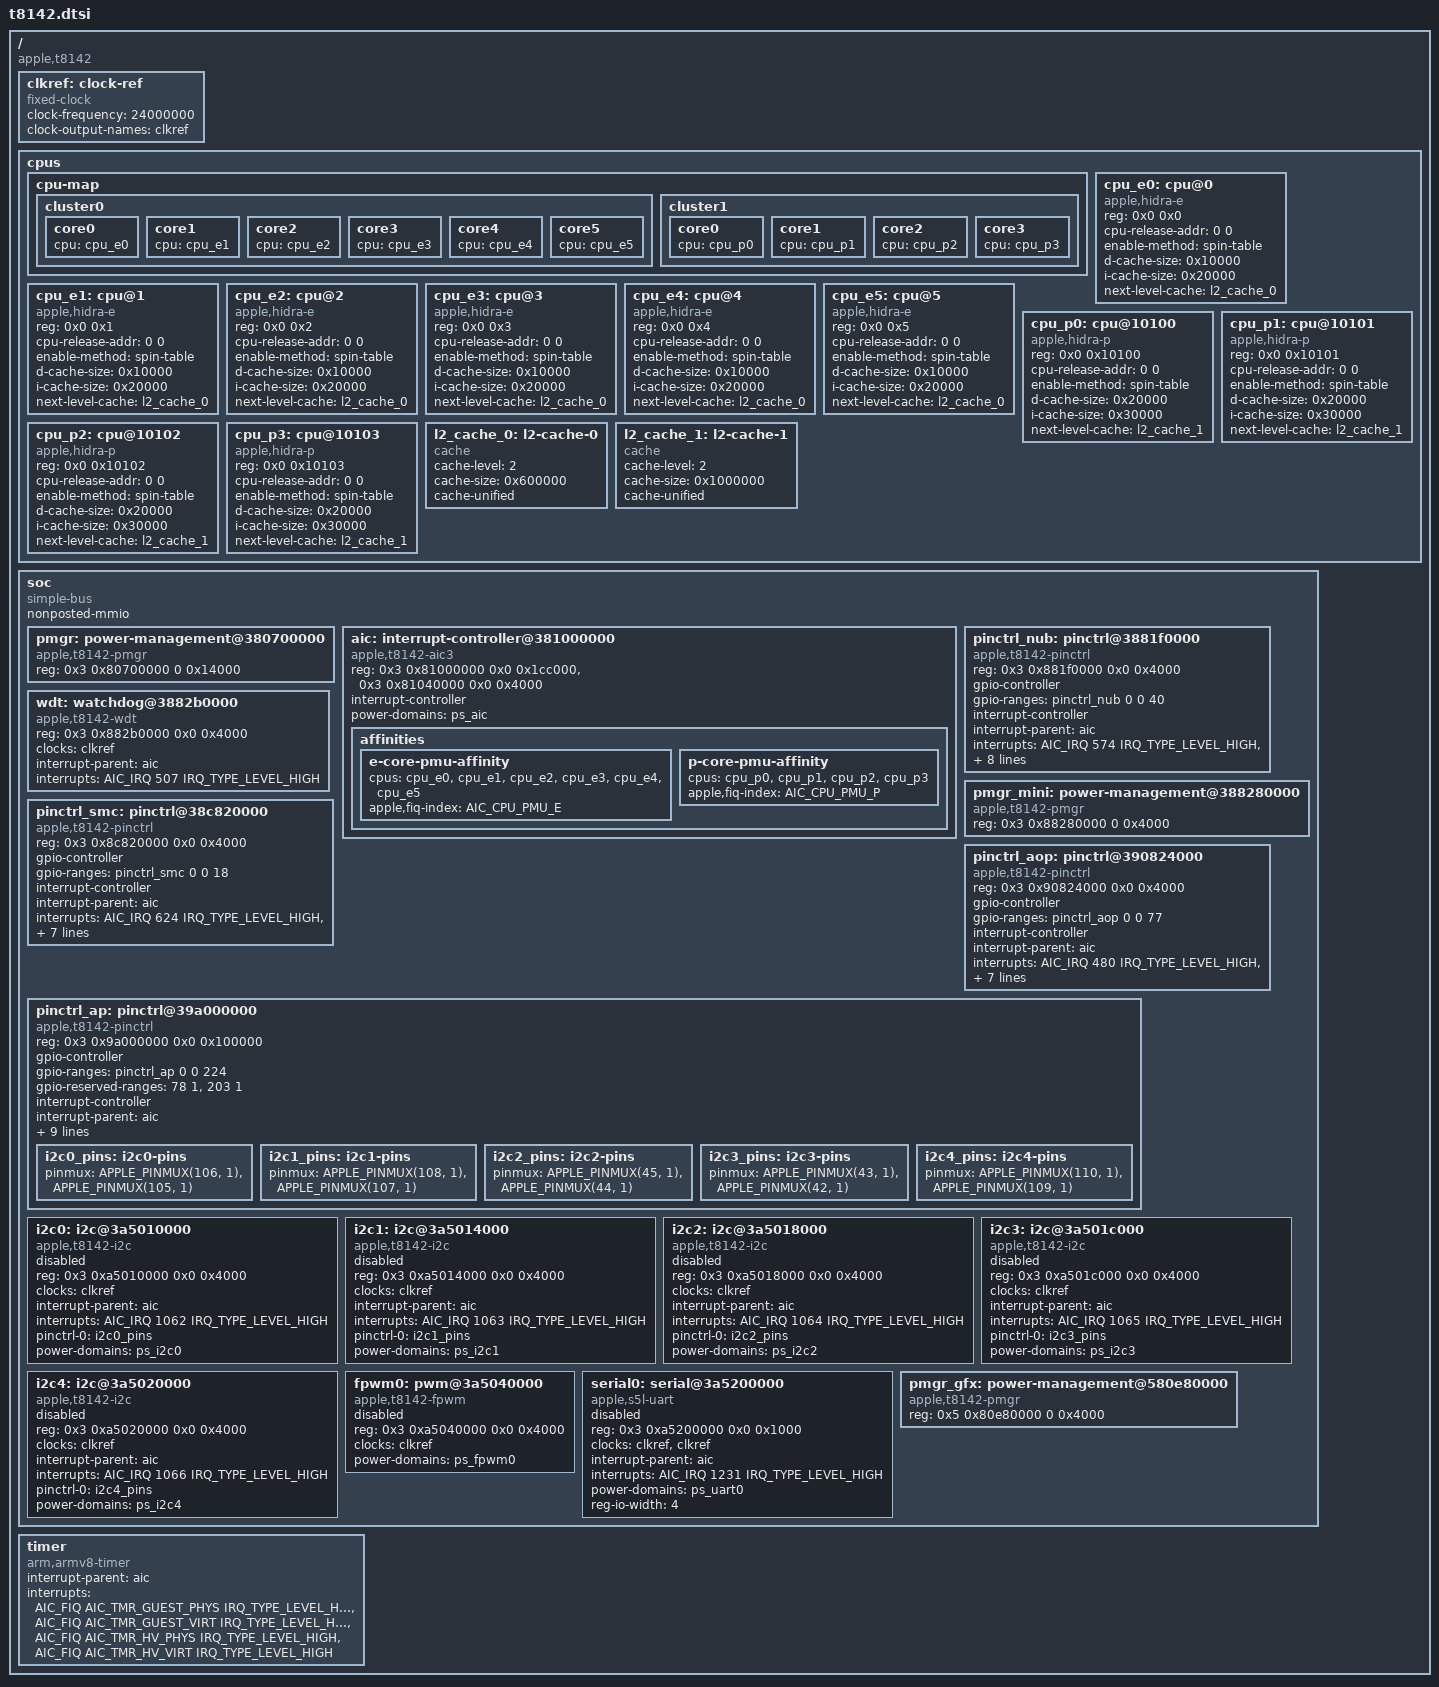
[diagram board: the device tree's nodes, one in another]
// SPDX-License-Identifier: GPL-2.0+ OR MIT
/*
 * Apple T8142 "M5" SoC
 *
 * Copyright The Asahi Linux Contributors
 */

#include <dt-bindings/interrupt-controller/apple-aic.h>
#include <dt-bindings/interrupt-controller/irq.h>
#include <dt-bindings/pinctrl/apple.h>

/ {
	compatible = "apple,t8142", "apple,arm-platform";

	#address-cells = <2>;
	#size-cells = <2>;

	clkref: clock-ref {
		compatible = "fixed-clock";
		#clock-cells = <0>;
		clock-frequency = <24000000>;
		clock-output-names = "clkref";
	};

	cpus {
		#address-cells = <2>;
		#size-cells = <0>;

		cpu-map {
			cluster0 {
				core0 {
					cpu = <&cpu_e0>;
				};

				core1 {
					cpu = <&cpu_e1>;
				};

				core2 {
					cpu = <&cpu_e2>;
				};

				core3 {
					cpu = <&cpu_e3>;
				};

				core4 {
					cpu = <&cpu_e4>;
				};

				core5 {
					cpu = <&cpu_e5>;
				};
			};

			cluster1 {
				core0 {
					cpu = <&cpu_p0>;
				};

				core1 {
					cpu = <&cpu_p1>;
				};

				core2 {
					cpu = <&cpu_p2>;
				};

				core3 {
					cpu = <&cpu_p3>;
				};
			};
		};

		cpu_e0: cpu@0 {
			device_type = "cpu";
			compatible = "apple,hidra-e";
			reg = <0x0 0x0>;
			cpu-release-addr = <0 0>;
			enable-method = "spin-table";

			d-cache-size = <0x10000>;
			i-cache-size = <0x20000>;
			next-level-cache = <&l2_cache_0>;
		};

		cpu_e1: cpu@1 {
			device_type = "cpu";
			compatible = "apple,hidra-e";
			reg = <0x0 0x1>;
			cpu-release-addr = <0 0>;
			enable-method = "spin-table";

			d-cache-size = <0x10000>;
			i-cache-size = <0x20000>;
			next-level-cache = <&l2_cache_0>;
		};

		cpu_e2: cpu@2 {
			device_type = "cpu";
			compatible = "apple,hidra-e";
			reg = <0x0 0x2>;
			cpu-release-addr = <0 0>;
			enable-method = "spin-table";

			d-cache-size = <0x10000>;
			i-cache-size = <0x20000>;
			next-level-cache = <&l2_cache_0>;
		};

		cpu_e3: cpu@3 {
			device_type = "cpu";
			compatible = "apple,hidra-e";
			reg = <0x0 0x3>;
			cpu-release-addr = <0 0>;
			enable-method = "spin-table";

			d-cache-size = <0x10000>;
			i-cache-size = <0x20000>;
			next-level-cache = <&l2_cache_0>;
		};

		cpu_e4: cpu@4 {
			device_type = "cpu";
			compatible = "apple,hidra-e";
			reg = <0x0 0x4>;
			cpu-release-addr = <0 0>;
			enable-method = "spin-table";

			d-cache-size = <0x10000>;
			i-cache-size = <0x20000>;
			next-level-cache = <&l2_cache_0>;
		};

		cpu_e5: cpu@5 {
			device_type = "cpu";
			compatible = "apple,hidra-e";
			reg = <0x0 0x5>;
			cpu-release-addr = <0 0>;
			enable-method = "spin-table";

			d-cache-size = <0x10000>;
			i-cache-size = <0x20000>;
			next-level-cache = <&l2_cache_0>;
		};

		cpu_p0: cpu@10100 {
			device_type = "cpu";
			compatible = "apple,hidra-p";
			reg = <0x0 0x10100>;
			cpu-release-addr = <0 0>;
			enable-method = "spin-table";

			d-cache-size = <0x20000>;
			i-cache-size = <0x30000>;
			next-level-cache = <&l2_cache_1>;
		};

		cpu_p1: cpu@10101 {
			device_type = "cpu";
			compatible = "apple,hidra-p";
			reg = <0x0 0x10101>;
			cpu-release-addr = <0 0>;
			enable-method = "spin-table";

			d-cache-size = <0x20000>;
			i-cache-size = <0x30000>;
			next-level-cache = <&l2_cache_1>;
		};

		cpu_p2: cpu@10102 {
			device_type = "cpu";
			compatible = "apple,hidra-p";
			reg = <0x0 0x10102>;
			cpu-release-addr = <0 0>;
			enable-method = "spin-table";

			d-cache-size = <0x20000>;
			i-cache-size = <0x30000>;
			next-level-cache = <&l2_cache_1>;
		};

		cpu_p3: cpu@10103 {
			device_type = "cpu";
			compatible = "apple,hidra-p";
			reg = <0x0 0x10103>;
			cpu-release-addr = <0 0>;
			enable-method = "spin-table";

			d-cache-size = <0x20000>;
			i-cache-size = <0x30000>;
			next-level-cache = <&l2_cache_1>;
		};

		l2_cache_0: l2-cache-0 {
			compatible = "cache";
			cache-level = <2>;
			cache-size = <0x600000>;
			cache-unified;
		};

		l2_cache_1: l2-cache-1 {
			compatible = "cache";
			cache-level = <2>;
			cache-size = <0x1000000>;
			cache-unified;
		};
	};

	soc: soc {
		compatible = "simple-bus";
		ranges;
		#address-cells = <2>;
		nonposted-mmio;
		#size-cells = <2>;

		pmgr: power-management@380700000 {
			compatible = "apple,t8142-pmgr", "apple,t8103-pmgr",
			             "syscon", "simple-mfd";
			reg = <0x3 0x80700000 0 0x14000>;
			#address-cells = <1>;
			#size-cells = <1>;
			/* child nodes are added in t8142-pmgr.dtsi */
		};

		aic: interrupt-controller@381000000 {
			compatible = "apple,t8142-aic3", "apple,t8122-aic3";
			reg = <0x3 0x81000000 0x0 0x1cc000>,
			      <0x3 0x81040000 0x0 0x4000>;
			reg-names = "core", "event";
			#interrupt-cells = <3>;
			interrupt-controller;
			power-domains = <&ps_aic>;

			affinities {
				e-core-pmu-affinity {
					cpus = <&cpu_e0 &cpu_e1 &cpu_e2
					        &cpu_e3 &cpu_e4 &cpu_e5>;
					apple,fiq-index = <AIC_CPU_PMU_E>;
				};

				p-core-pmu-affinity {
					cpus = <&cpu_p0 &cpu_p1
					        &cpu_p2 &cpu_p3>;
					apple,fiq-index = <AIC_CPU_PMU_P>;
				};
			};
		};

		pinctrl_nub: pinctrl@3881f0000 {
			compatible = "apple,t8142-pinctrl",
			             "apple,t8140-pinctrl";
			reg = <0x3 0x881f0000 0x0 0x4000>;

			#gpio-cells = <2>;
			gpio-controller;
			gpio-ranges = <&pinctrl_nub 0 0 40>;

			#interrupt-cells = <2>;
			interrupt-controller;
			interrupt-parent = <&aic>;
			interrupts = <AIC_IRQ 574 IRQ_TYPE_LEVEL_HIGH>,
			             <AIC_IRQ 575 IRQ_TYPE_LEVEL_HIGH>,
			             <AIC_IRQ 576 IRQ_TYPE_LEVEL_HIGH>,
			             <AIC_IRQ 577 IRQ_TYPE_LEVEL_HIGH>,
			             <AIC_IRQ 578 IRQ_TYPE_LEVEL_HIGH>,
			             <AIC_IRQ 579 IRQ_TYPE_LEVEL_HIGH>,
			             <AIC_IRQ 580 IRQ_TYPE_LEVEL_HIGH>;

			power-domains = <&ps_nub_gpio>;
			apple,npins = <40>;
		};

		pmgr_mini: power-management@388280000 {
			compatible = "apple,t8142-pmgr", "apple,t8103-pmgr",
			             "syscon", "simple-mfd";
			reg = <0x3 0x88280000 0 0x4000>;
			#address-cells = <1>;
			#size-cells = <1>;
			/* child nodes are added in t8142-pmgr.dtsi */
		};

		wdt: watchdog@3882b0000 {
			compatible = "apple,t8142-wdt", "apple,t8103-wdt";
			reg = <0x3 0x882b0000 0x0 0x4000>;
			clocks = <&clkref>;
			interrupt-parent = <&aic>;
			interrupts = <AIC_IRQ 507 IRQ_TYPE_LEVEL_HIGH>;
		};

		pinctrl_smc: pinctrl@38c820000 {
			compatible = "apple,t8142-pinctrl",
			             "apple,t8140-pinctrl";
			reg = <0x3 0x8c820000 0x0 0x4000>;

			#gpio-cells = <2>;
			gpio-controller;
			gpio-ranges = <&pinctrl_smc 0 0 18>;

			#interrupt-cells = <2>;
			interrupt-controller;
			interrupt-parent = <&aic>;
			interrupts = <AIC_IRQ 624 IRQ_TYPE_LEVEL_HIGH>,
			             <AIC_IRQ 625 IRQ_TYPE_LEVEL_HIGH>,
			             <AIC_IRQ 626 IRQ_TYPE_LEVEL_HIGH>,
			             <AIC_IRQ 627 IRQ_TYPE_LEVEL_HIGH>,
			             <AIC_IRQ 628 IRQ_TYPE_LEVEL_HIGH>,
			             <AIC_IRQ 629 IRQ_TYPE_LEVEL_HIGH>,
			             <AIC_IRQ 630 IRQ_TYPE_LEVEL_HIGH>;

			apple,npins = <18>;
		};

		pinctrl_aop: pinctrl@390824000 {
			compatible = "apple,t8142-pinctrl",
			             "apple,t8140-pinctrl";
			reg = <0x3 0x90824000 0x0 0x4000>;

			#gpio-cells = <2>;
			gpio-controller;
			gpio-ranges = <&pinctrl_aop 0 0 77>;

			#interrupt-cells = <2>;
			interrupt-controller;
			interrupt-parent = <&aic>;
			interrupts = <AIC_IRQ 480 IRQ_TYPE_LEVEL_HIGH>,
			             <AIC_IRQ 481 IRQ_TYPE_LEVEL_HIGH>,
			             <AIC_IRQ 482 IRQ_TYPE_LEVEL_HIGH>,
			             <AIC_IRQ 483 IRQ_TYPE_LEVEL_HIGH>,
			             <AIC_IRQ 484 IRQ_TYPE_LEVEL_HIGH>,
			             <AIC_IRQ 485 IRQ_TYPE_LEVEL_HIGH>,
			             <AIC_IRQ 486 IRQ_TYPE_LEVEL_HIGH>;

			apple,npins = <77>;
		};

		pinctrl_ap: pinctrl@39a000000 {
			compatible = "apple,t8142-pinctrl",
			             "apple,t8140-pinctrl";
			reg = <0x3 0x9a000000 0x0 0x100000>;

			#gpio-cells = <2>;
			gpio-controller;
			gpio-ranges = <&pinctrl_ap 0 0 224>;
			gpio-reserved-ranges = <78 1>, <203 1>;

			#interrupt-cells = <2>;
			interrupt-controller;
			interrupt-parent = <&aic>;
			interrupts = <AIC_IRQ 347 IRQ_TYPE_LEVEL_HIGH>,
			             <AIC_IRQ 348 IRQ_TYPE_LEVEL_HIGH>,
			             <AIC_IRQ 349 IRQ_TYPE_LEVEL_HIGH>,
			             <AIC_IRQ 350 IRQ_TYPE_LEVEL_HIGH>,
			             <AIC_IRQ 351 IRQ_TYPE_LEVEL_HIGH>,
			             <AIC_IRQ 352 IRQ_TYPE_LEVEL_HIGH>,
			             <AIC_IRQ 353 IRQ_TYPE_LEVEL_HIGH>;

			power-domains = <&ps_gpio>;
			apple,npins = <224>;

			i2c0_pins: i2c0-pins {
				pinmux = <APPLE_PINMUX(106, 1)>,
				         <APPLE_PINMUX(105, 1)>;
			};

			i2c1_pins: i2c1-pins {
				pinmux = <APPLE_PINMUX(108, 1)>,
				         <APPLE_PINMUX(107, 1)>;
			};

			i2c2_pins: i2c2-pins {
				pinmux = <APPLE_PINMUX(45, 1)>,
				         <APPLE_PINMUX(44, 1)>;
			};

			i2c3_pins: i2c3-pins {
				pinmux = <APPLE_PINMUX(43, 1)>,
				         <APPLE_PINMUX(42, 1)>;
			};

			i2c4_pins: i2c4-pins {
				pinmux = <APPLE_PINMUX(110, 1)>,
				         <APPLE_PINMUX(109, 1)>;
			};
		};

		i2c0: i2c@3a5010000 {
			compatible = "apple,t8142-i2c", "apple,t8103-i2c";
			reg = <0x3 0xa5010000 0x0 0x4000>;

			#address-cells = <0x1>;
			clocks = <&clkref>;
			interrupt-parent = <&aic>;
			interrupts = <AIC_IRQ 1062 IRQ_TYPE_LEVEL_HIGH>;
			pinctrl-0 = <&i2c0_pins>;
			pinctrl-names = "default";
			power-domains = <&ps_i2c0>;
			#size-cells = <0x0>;

			status = "disabled";
		};

		i2c1: i2c@3a5014000 {
			compatible = "apple,t8142-i2c", "apple,t8103-i2c";
			reg = <0x3 0xa5014000 0x0 0x4000>;

			#address-cells = <0x1>;
			clocks = <&clkref>;
			interrupt-parent = <&aic>;
			interrupts = <AIC_IRQ 1063 IRQ_TYPE_LEVEL_HIGH>;
			pinctrl-0 = <&i2c1_pins>;
			pinctrl-names = "default";
			power-domains = <&ps_i2c1>;
			#size-cells = <0x0>;

			status = "disabled";
		};

		i2c2: i2c@3a5018000 {
			compatible = "apple,t8142-i2c", "apple,t8103-i2c";
			reg = <0x3 0xa5018000 0x0 0x4000>;

			#address-cells = <0x1>;
			clocks = <&clkref>;
			interrupt-parent = <&aic>;
			interrupts = <AIC_IRQ 1064 IRQ_TYPE_LEVEL_HIGH>;
			pinctrl-0 = <&i2c2_pins>;
			pinctrl-names = "default";
			power-domains = <&ps_i2c2>;
			#size-cells = <0x0>;

			status = "disabled";
		};

		i2c3: i2c@3a501c000 {
			compatible = "apple,t8142-i2c", "apple,t8103-i2c";
			reg = <0x3 0xa501c000 0x0 0x4000>;

			#address-cells = <0x1>;
			clocks = <&clkref>;
			interrupt-parent = <&aic>;
			interrupts = <AIC_IRQ 1065 IRQ_TYPE_LEVEL_HIGH>;
			pinctrl-0 = <&i2c3_pins>;
			pinctrl-names = "default";
			power-domains = <&ps_i2c3>;
			#size-cells = <0x0>;

			status = "disabled";
		};

		i2c4: i2c@3a5020000 {
			compatible = "apple,t8142-i2c", "apple,t8103-i2c";
			reg = <0x3 0xa5020000 0x0 0x4000>;

			#address-cells = <0x1>;
			clocks = <&clkref>;
			interrupt-parent = <&aic>;
			interrupts = <AIC_IRQ 1066 IRQ_TYPE_LEVEL_HIGH>;
			pinctrl-0 = <&i2c4_pins>;
			pinctrl-names = "default";
			power-domains = <&ps_i2c4>;
			#size-cells = <0x0>;

			status = "disabled";
		};

		fpwm0: pwm@3a5040000 {
			compatible = "apple,t8142-fpwm", "apple,s5l-fpwm";
			reg = <0x3 0xa5040000 0x0 0x4000>;

			clocks = <&clkref>;
			power-domains = <&ps_fpwm0>;
			#pwm-cells = <2>;

			status = "disabled";
		};

		serial0: serial@3a5200000 {
			compatible = "apple,s5l-uart";
			reg = <0x3 0xa5200000 0x0 0x1000>;

			clocks = <&clkref>, <&clkref>;
			clock-names = "uart", "clk_uart_baud0";
			interrupt-parent = <&aic>;
			interrupts = <AIC_IRQ 1231 IRQ_TYPE_LEVEL_HIGH>;
			power-domains = <&ps_uart0>;
			reg-io-width = <4>;

			status = "disabled";
		};

		pmgr_gfx: power-management@580e80000 {
			compatible = "apple,t8142-pmgr", "apple,t8103-pmgr",
			             "syscon", "simple-mfd";
			reg = <0x5 0x80e80000 0 0x4000>;
			#address-cells = <1>;
			#size-cells = <1>;
		};
	};

	timer {
		compatible = "arm,armv8-timer";
		interrupt-parent = <&aic>;
		interrupts = <AIC_FIQ AIC_TMR_GUEST_PHYS IRQ_TYPE_LEVEL_HIGH>,
		             <AIC_FIQ AIC_TMR_GUEST_VIRT IRQ_TYPE_LEVEL_HIGH>,
		             <AIC_FIQ AIC_TMR_HV_PHYS IRQ_TYPE_LEVEL_HIGH>,
		             <AIC_FIQ AIC_TMR_HV_VIRT IRQ_TYPE_LEVEL_HIGH>;
		interrupt-names = "phys", "virt", "hyp-phys", "hyp-virt";
	};
};

#include "t8142-pmgr.dtsi"
